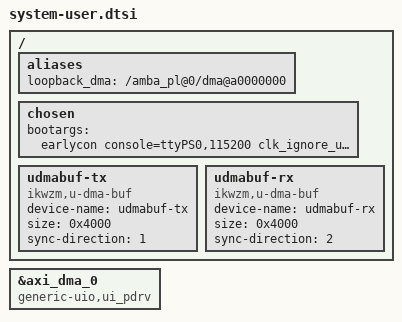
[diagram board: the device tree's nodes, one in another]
/include/ "system-conf.dtsi"
/ {
        aliases {
              /delete-property/ axi_dma_0;
              loopback_dma = "/amba_pl@0/dma@a0000000";

        };

        chosen {
              bootargs = "earlycon console=ttyPS0,115200 clk_ignore_unused uio_pdrv_genirq.of_id=generic-uio,ui_pdrv root=/dev/ram0 rw";
        };
	
        udmabuf-tx {
              compatible  = "ikwzm,u-dma-buf";
              device-name = "udmabuf-tx";
              size = <0x4000>;
              sync-direction = <1>;
        };

        udmabuf-rx {
              compatible  = "ikwzm,u-dma-buf";
              device-name = "udmabuf-rx";
              size = <0x4000>;
              sync-direction = <2>;
        };
};

&axi_dma_0 {
        compatible = "generic-uio,ui_pdrv";
};

